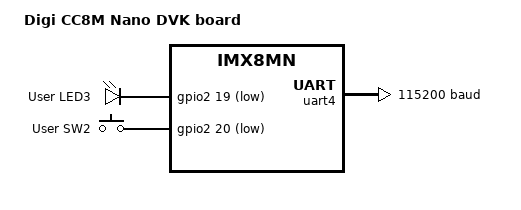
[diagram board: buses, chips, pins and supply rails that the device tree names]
/*
 * Copyright (c) 2021, Waseem Hassan
 *
 * SPDX-License-Identifier: Apache-2.0
 */

/dts-v1/;

#include <nxp/nxp_imx8mn_m7.dtsi>

/ {
	model = "Digi CC8M Nano DVK board";
	compatible = "nxp,cc8mnano_dvk";

	aliases {
		led0 = &red_led;
		uart-4 = &uart4;
		sw0    = &user_switch_2;
	};

	chosen {
		zephyr,flash = &itcm;
		zephyr,sram = &dtcm;
		zephyr,console = &uart4;
		zephyr,shell-uart = &uart4;
	};

	leds {
		compatible = "gpio-leds";
		red_led: led_0 {
			gpios = <&gpio2 19 GPIO_ACTIVE_LOW>;
			label = "User LED3";
		};
	};

	gpio_keys {
		compatible = "gpio-keys";
		user_switch_2: user_sw_2 {
			gpios = <&gpio2 20 GPIO_ACTIVE_LOW>;
			label = "User SW2";
		};
	};
			
};

&uart4 {
	status = "okay";
	current-speed = <115200>;
};

&gpio2 {
	status = "okay";
};
